# R40 register map
Vendor: Allwinner; Series: R40; File version: 0.1
CPU: CA7 0, little endian, MPU, FPU, double-precision FPU, 0 interrupt priority bits
Registers are 32-bit, read-write, reset 0x0 unless marked. A register's access mark holds for its fields unless they carry their own. Offsets are from the block's base; [hi:lo] are bit positions; lines under a group give offsets from that group; {n}, {i} and the like mark numbered series; 'fields as' and 'values as' point back to an identical list.

## PWM
Base 0x01C23400
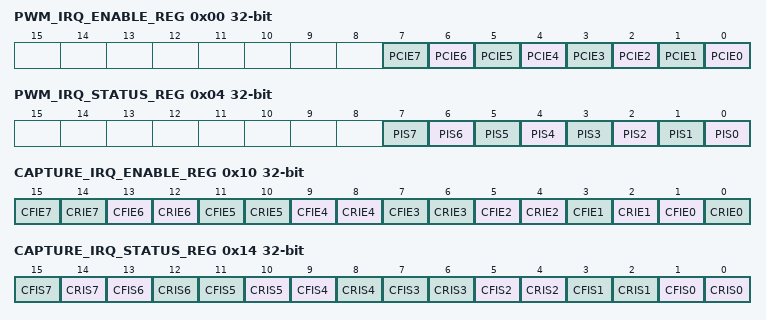
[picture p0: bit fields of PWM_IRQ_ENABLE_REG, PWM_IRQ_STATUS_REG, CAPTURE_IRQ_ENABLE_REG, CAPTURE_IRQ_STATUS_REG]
0x00 PWM_IRQ_ENABLE_REG
  [n] PCIE{n} (n=0..7) — PWM channel {n} Interrupt Enable. 0: PWM channel {n} Interrupt Disable 1: PWM channel {n} Interrupt Enable
    0=PWM_channel_{n}_Interrupt_Disable; 1=PWM_channel_{n}_Interrupt_Enable
0x04 PWM_IRQ_STATUS_REG
  [n] PIS{n} write-1-clears (n=0..7) — PWM channel {n} Interrupt Status. When PWM channel {n} counter reaches Entire Cycle Value, this bit is set to 1 by hardware. Write 1 to clear this bit. Reads 0: PWM channel {n} interrupt is not pending. 1: PWM channel {n} interrupt is pending. Writes 0: No effect. 1: Clear PWM channel {n} interrupt status.
0x10 CAPTURE_IRQ_ENABLE_REG
  [2n+1] CFIE{n} (n=0..7) — If this enable bit is set to 1, when capture channel {n} captures falling edge, it generates a capture channel {n} pending. 0: Capture channel {n} fall lock interrupt disable 1: Capture channel {n} fall lock interrupt enable
    0=Capture_channel_{n}_fall_lock_interrupt_disable; 1=Capture_channel_{n}_fall_lock_interrupt_enable
  [2n] CRIE{n} (n=2..7) — If this enable bit is set to 1, when capture channel {n} captures rising edge, it generates a capture channel {n} pending. 0: Capture channel {n} rise lock interrupt disable 1: Capture channel {n} rise lock interrupt enable
    0=Capture_channel_{n}_rise_lock_interrupt_disable; 1=Capture_channel_{n}_rise_lock_interrupt_enable
  [2] CRIE1 — If this enable bit is set 1, when capture channel 1 captures rising edge, it generates a capture channel 1 pending. 0: Capture channel 1 rise lock Interrupt disable 1: Capture channel 1 rise lock Interrupt enable
    0=Capture_channel_1_rise_lock_Interrupt_disable; 1=Capture_channel_1_rise_lock_Interrupt_enable
  [0] CRIE0 — If this enable bit is set to 1, when capture channel 0 captures rising edge, it generates a capture channel 0 pending. 0: Capture channel 0 rise lock interrupt disable 1: Capture channel 0 rise lock interrupt enable
    0=Capture_channel_0_rise_lock_interrupt_disable; 1=Capture_channel_0_rise_lock_interrupt_enable
0x14 CAPTURE_IRQ_STATUS_REG
  [2n+1] CFIS{n} write-1-clears (n=0..7) — Capture channel {n} falling lock interrupt status. When capture channel {n} captures falling edge, if capture channel {n} fall lock interrupt ( ) is enabled, this bit is set to 1 by hardware. Write 1 to clear this bit. Reads 0: Capture channel {n} interrupt is not pending. 1: Capture channel {n} interrupt is pending. Writes 0: No effect. 1: Clear capture channel {n} interrupt status.
  [14] CRIS7 write-1-clears — Capture channel 7 rising lock interrupt status. When capture channel 7 captures rising edge, if capture channel 7 rise lock interrupt ( ) is enabled, this bit is set to 1 by hardware. Write 1 to clear this bit. Reads 0: Capture channel 7 interrupt is not pending. 1: Capture channel 7 interrupt is pending. Writes 0: No effect. 1: Clear capture channel 7 interrupt status.
  [12] CRIS6 write-1-clears — Capture channel 6 rising lock interrupt status. When capture channel 6 captures rising edge, if capture channel 6 rise lock interrupt ( ) is enabled, this bit is set to 1 by hardware. Write 1 to clear this bit. Reads 0: Capture channel 6 interrupt is not pending. 1: Capture channel 6 interrupt is pending. Writes 0: No effect. 1: Clear capture channel 6 interrupt status.
  [10] CRIS5 write-1-clears — Capture channel 5 rising lock interrupt status. When capture channel 5 captures rising edge, if capture channel 5 rise lock interrupt ( ) is enabled, this bit is set to 1 by hardware. Write 1 to clear this bit. Reads 0: Capture channel 5 interrupt is not pending. 1: Capture channel 5 interrupt is pending. Writes 0: No effect. 1: Clear capture channel 5 interrupt status.
  [8] CRIS4 write-1-clears — Capture channel 4 rising lock interrupt status. When capture channel 4 captures rising edge, if capture channel 4 rise lock interrupt ( ) is enabled, this bit is set to 1 by hardware. Write 1 to clear this bit. Reads 0: Capture channel 4 interrupt is not pending. 1: Capture channel 4 interrupt is pending. Writes 0: no effect. 1: Clear capture channel 4 interrupt status.
  [2n] CRIS{n} write-1-clears (n=0..3) — Capture channel {n} rising lock interrupt status. When capture channel {n} captures rising edge, if capture channel {n} rise lock interrupt ( ) is enabled, this bit is set to 1 by hardware. Write 1 to clear this bit. Reads 0: Capture channel {n} interrupt is not pending. 1: Capture channel {n} interrupt is pending. Writes 0: No effect. 1: Clear capture channel {n} interrupt status.
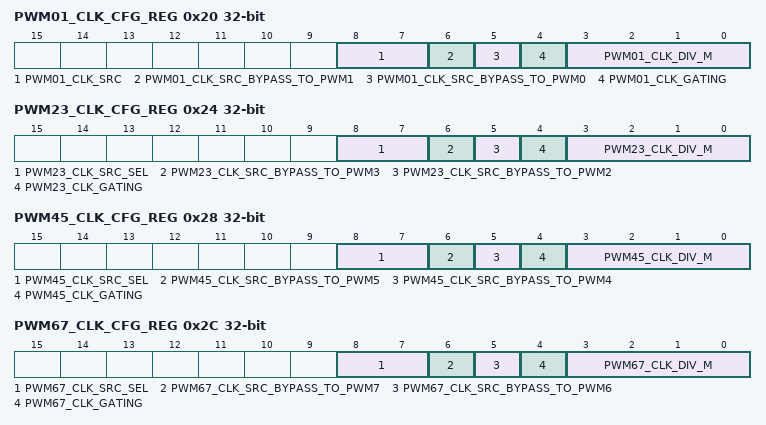
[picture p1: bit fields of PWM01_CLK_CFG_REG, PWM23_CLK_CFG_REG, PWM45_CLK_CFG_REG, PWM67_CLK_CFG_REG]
0x20 PWM01_CLK_CFG_REG
  [8:7] PWM01_CLK_SRC — Select PWM01 clock source. 00: 24M_PLL 01: APB1 Others: /
    0=_24M_PLL; 1=APB1 (APB1 Others: /)
  [6] PWM01_CLK_SRC_BYPASS_TO_PWM1 — Bypass PWM01 clock source to PWM1 output. 0: Not bypass 1: Bypass
    0=Not_bypass; 1=Bypass
  [5] PWM01_CLK_SRC_BYPASS_TO_PWM0 — Bypass PWM01 clock source to PWM0 output. 0: Not bypass 1: Bypass
    0=Not_bypass; 1=Bypass
  [4] PWM01_CLK_GATING — Gating clock for PWM01. 0: Mask 1: Pass
    0=Mask; 1=Pass
  [3:0] PWM01_CLK_DIV_M — PWM01 clock divide M 0000: /1 0001: /2 0010: /4 0011: /8 0100: /16 0101: /32 0110: /64 0111: /128 1000: /256 others: /
    0=_slash_1 (/1); 1=_slash_2 (/2); 2=_slash_4 (/4); 3=_slash_8 (/8); 4=_slash_16 (/16); 5=_slash_32 (/32); 6=_slash_64 (/64); 7=_slash_128 (/128); 8=_slash_256 (/256 others: /)
0x24 PWM23_CLK_CFG_REG
  [8:7] PWM23_CLK_SRC_SEL — Select PWM23 clock source. 00: 24M_PLL 01: APB1 Others: /
    0=_24M_PLL; 1=APB1 (APB1 Others: /)
  [6] PWM23_CLK_SRC_BYPASS_TO_PWM3 — Bypass PWM23 clock source to PWM3 output. 0: Not bypass 1: Bypass
    0=Not_bypass; 1=Bypass
  [5] PWM23_CLK_SRC_BYPASS_TO_PWM2 — Bypass PWM23 clock source to PWM2 output. 0: Not bypass 1: Bypass
    0=Not_bypass; 1=Bypass
  [4] PWM23_CLK_GATING — Gating clock for PWM23. 0: Mask 1: Pass
    0=Mask; 1=Pass
  [3:0] PWM23_CLK_DIV_M — PWM23 clock divide M 0000: /1 0001: /2 0010: /4 0011: /8 0100: /16 0101: /32 0110: /64 0111: /128 1000: /256 others: /
    values as PWM01_CLK_CFG_REG.PWM01_CLK_DIV_M
0x28 PWM45_CLK_CFG_REG
  [8:7] PWM45_CLK_SRC_SEL — Select PWM45 clock source. 00: 24M_PLL 01: APB1 Others: /
    0=_24M_PLL; 1=APB1 (APB1 Others: /)
  [6] PWM45_CLK_SRC_BYPASS_TO_PWM5 — Bypass PWM45 clock source to PWM5 output. 0: Not bypass 1: Bypass
    0=Not_bypass; 1=Bypass
  [5] PWM45_CLK_SRC_BYPASS_TO_PWM4 — Bypass PWM45 clock source to PWM4 output. 0: Not bypass 1: Bypass
    0=Not_bypass; 1=Bypass
  [4] PWM45_CLK_GATING — Gating clock for PWM45. 0: Mask 1: Pass
    0=Mask; 1=Pass
  [3:0] PWM45_CLK_DIV_M — PWM45 clock divide M 0000: /1 0001: /2 0010: /4 0011: /8 0100: /16 0101: /32 0110: /64 0111: /128 1000: /256 others: /
    values as PWM01_CLK_CFG_REG.PWM01_CLK_DIV_M
0x2C PWM67_CLK_CFG_REG
  [8:7] PWM67_CLK_SRC_SEL — Select PWM67 clock source. 00: 24M_PLL 01: APB1 Others: /
    0=_24M_PLL; 1=APB1 (APB1 Others: /)
  [6] PWM67_CLK_SRC_BYPASS_TO_PWM7 — Bypass PWM67 clock source to PWM7 output. 0: Not bypass 1: Bypass
    0=Not_bypass; 1=Bypass
  [5] PWM67_CLK_SRC_BYPASS_TO_PWM6 — Bypass PWM67 clock source to PWM6 output. 0: Not bypass 1: Bypass
    0=Not_bypass; 1=Bypass
  [4] PWM67_CLK_GATING — Gating clock for PWM67. 0: Mask 1: Pass
    0=Mask; 1=Pass
  [3:0] PWM67_CLK_DIV_M — PWM67 clock divide M 0000: /1 0001: /2 0010: /4 0011: /8 0100: /16 0101: /32 0110: /64 0111: /128 1000: /256 others: /
    values as PWM01_CLK_CFG_REG.PWM01_CLK_DIV_M
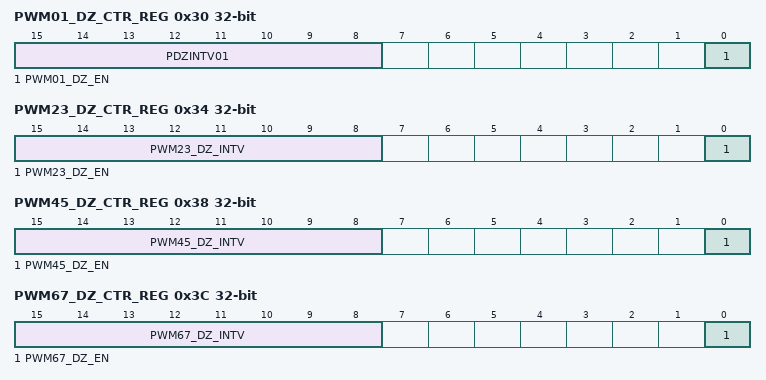
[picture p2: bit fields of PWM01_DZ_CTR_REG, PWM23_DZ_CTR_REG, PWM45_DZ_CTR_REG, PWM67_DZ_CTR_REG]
0x30 PWM01_DZ_CTR_REG
  [15:8] PDZINTV01 — PWM01 Dead Zone interval value.
  [0] PWM01_DZ_EN — PWM01 Dead Zone enable. 0: Dead Zone disable 1: Dead Zone enable.
    0=Dead_Zone_disable; 1=Dead Zone enable
0x34 PWM23_DZ_CTR_REG
  [15:8] PWM23_DZ_INTV — PWM23 Dead Zone interval value.
  [0] PWM23_DZ_EN — PWM23 Dead Zone enable. 0: Dead Zone disable 1: Dead Zone enable.
    0=Dead_Zone_disable; 1=Dead Zone enable
0x38 PWM45_DZ_CTR_REG
  [15:8] PWM45_DZ_INTV — PWM45 Dead Zone interval value.
  [0] PWM45_DZ_EN — PWM45 Dead Zone enable. 0: Dead Zone disable 1: Dead Zone enable.
    0=Dead_Zone_disable; 1=Dead Zone enable
0x3C PWM67_DZ_CTR_REG
  [15:8] PWM67_DZ_INTV — PWM67 Dead Zone interval value.
  [0] PWM67_DZ_EN — PWM67 Dead Zone enable. 0: Dead Zone disable 1: Dead Zone enable.
    0=Dead_Zone_disable; 1=Dead Zone enable
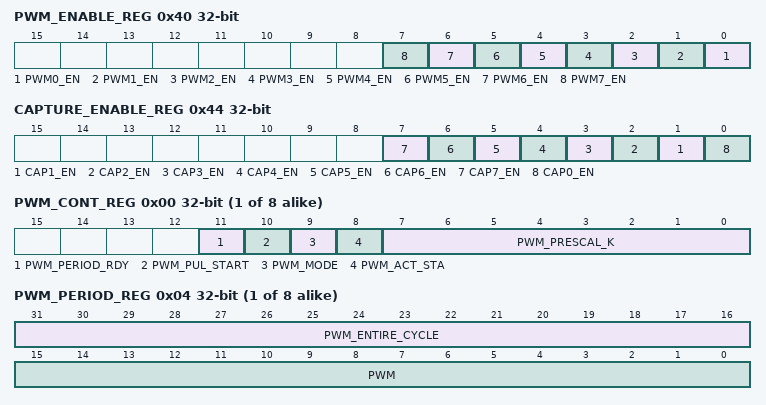
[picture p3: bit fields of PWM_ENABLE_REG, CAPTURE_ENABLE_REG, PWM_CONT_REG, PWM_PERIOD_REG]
0x40 PWM_ENABLE_REG
  [all] fields
    0=PWM_disable; 1=PWM (PWM enable.)
  [n] PWM{n}_EN (n=0..7) — When enable PWM, the 16-bit up-counter starts working and PWM channel{n} is permitted to output PWM waveform. 0: PWM disable 1: PWM enable.
0x44 CAPTURE_ENABLE_REG
  [all] fields
    0=Capture_disable; 1=Capture enable
  [n] CAP{n}_EN (n=1..7) — When enable capture function, the 16-bit up-counter starts working and capture channel{n} is permitted to capture external falling edge or rising edge. 0: Capture disable 1: Capture enable.
  [0] CAP0_EN — When enable capture function, the 16-bit up-counter starts working and capture channel is permitted to capture external falling edge or rising edge. 0: Capture disable 1: Capture enable.
{0x60+0x20*i} _N[{i}] (i=0..7) group
  0x00 PWM_CONT_REG
    [11] PWM_PERIOD_RDY ro — PWM period register ready. 0: PWM period register is ready to write 1: PWM period register is busy.
      0=ready (PWM period register is ready to write); 1=busy (PWM period register is busy.)
    [10] PWM_PUL_START write-1-sets — PWM pulse output start. 0: No effect 1: Output 1 pulse. After finishing configurating for outputting pulse, set this bit once and then PWM would output one pulse. After the pulse is finished, the bit will be cleared automatically.
      0=No_effect; 1=Output 1 pulse. After finishing configurating for outputting pulse, set this bit once and then PWM would output one pulse. After the pulse is finished, the bit will be cleared automatically.
    [9] PWM_MODE — PWM output mode select. 0: Cycle mode 1: Pulse mode.
      0=Cycle_mode; 1=Pulse mode
    [8] PWM_ACT_STA — PWM active state. 0: Low Level 1: High Level.
      0=Low_Level; 1=High Level
    [7:0] PWM_PRESCAL_K — PWM pre-scale K, actual pre-scale is (K+1). K = 0, actual pre-scale: 1 K = 1, actual pre-scale: 2 K = 2, actual pre-scale: 3 K = 3, actual pre-scale: 4 ... K = 255, actual pre-scale: 256.
  0x04 PWM_PERIOD_REG
    [31:16] PWM_ENTIRE_CYCLE — Number of the entire cycles in the PWM clock. 0 = 1 cycle 1 = 2 cycles ... N = N+1 cycles If the register need to be modified dynamically, the PCLK should be faster than the PWM CLK .
    [15:0] PWM — _ACT_CYCLE. Number of the active cycles in the PWM clock. 0 = 0 cycle 1 = 1 cycles ... N = N cycles
  0x08 PWM_CTR_REG
    [15:0] ON ro — On PWM output or capture input, reading this register could get the current value of the PWM 16bit up-counter.
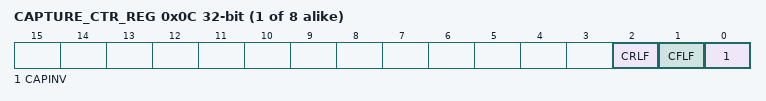
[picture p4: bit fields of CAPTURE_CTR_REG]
  0x0C CAPTURE_CTR_REG
    [2] CRLF — When capture channel captures rising edge, the 16-bit up-counter`s current value is latched to and then this bit is set to 1 by hardware. Write 1 to clear this bit.
    [1] CFLF — When capture channel captures falling edge, the 16-bit up-counter`s current value is latched to and then this bit is set to 1 by hardware. Write 1 to clear this bit.
    [0] CAPINV — Inversing the signal inputted form capture channel before capture channel's 16bit counter. 0: Not inverse 1: Inverse
      0=Not_inverse; 1=Inverse
  0x10 CAPTURE_RISE_REG
    [15:0] CRLR ro — When capture channel captures rising edge, the 16-bit up-counter`s current value is latched to this register.
  0x14 CAPTURE_FALL_REG
    [15:0] CFLR ro — When capture channel captures falling edge, the 16-bit up-counter`s current value is latched to this register.
